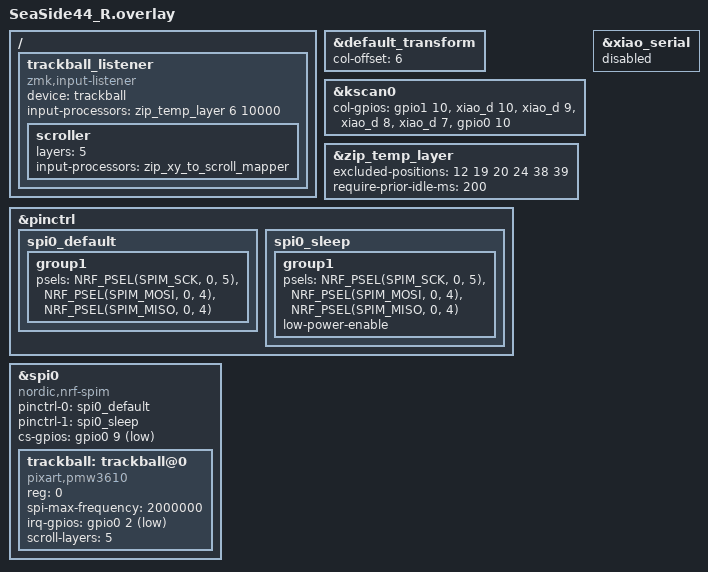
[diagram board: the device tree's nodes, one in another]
#include "SeaSide44.dtsi"
#include <input/processors.dtsi>

&default_transform {
    col-offset = <6>;
};

/* キーマトリクスの設定 */
// 上が外側、下が内側カラムcol番号と実際の配置が直感と逆になってる
&kscan0 {
        col-gpios
            = <&gpio1 10 GPIO_ACTIVE_HIGH>
            , <&xiao_d 10 GPIO_ACTIVE_HIGH>
            , <&xiao_d 9 GPIO_ACTIVE_HIGH> 
            , <&xiao_d 8 GPIO_ACTIVE_HIGH> 
            , <&xiao_d 7 GPIO_ACTIVE_HIGH> 
            , <&gpio0 10 GPIO_ACTIVE_HIGH>
            ;
};

/* AML: Input Processor: excluded-positions */
/* こちらに設定しているキー以外が入力されたらAML解除 */
&zip_temp_layer {
    excluded-positions = <
        12 // LCTRL
        19 // J
        20 // K
        24 // LSHIFT
        38 // LEFT_WIN
        39 // LEFT_ALT
    >;
    require-prior-idle-ms = <200>;
};

/* Trackball のリスナー */ 
/ {
    trackball_listener {
        compatible = "zmk,input-listener";
        device = <&trackball>;

        input-processors = <&zip_temp_layer 6 10000>;
    
        // セミコロン長押しで入る SCROLL(L5) が有効な間だけ
        // トラックボールの XY をスクロールイベントに変換する
        scroller {
            layers = <5>;
            input-processors = <&zip_xy_to_scroll_mapper>;
            // 必要なら感度を調整（例: 倍率や加速度を入れる場合）
            // scale-x = <1>;
            // scale-y = <1>;
            // invert-y;  // 逆方向が好みなら有効化
        };
    };
};

/* SPI 設定 */
&pinctrl {
    spi0_default: spi0_default {
        group1 {
            psels = <NRF_PSEL(SPIM_SCK, 0, 5)>,
                <NRF_PSEL(SPIM_MOSI, 0, 4)>,
                <NRF_PSEL(SPIM_MISO, 0, 4)>;
        };
    };

    spi0_sleep: spi0_sleep {
        group1 {
            psels = <NRF_PSEL(SPIM_SCK, 0, 5)>,
                <NRF_PSEL(SPIM_MOSI, 0, 4)>,
                <NRF_PSEL(SPIM_MISO, 0, 4)>;
            low-power-enable;
        };
    };
};

/* シリアルを無効化 */
&xiao_serial { status = "disabled"; };

/* SPI デバイス (トラックボール) */
&spi0 {
    status = "okay";
    compatible = "nordic,nrf-spim";
    pinctrl-0 = <&spi0_default>;
    pinctrl-1 = <&spi0_sleep>;
    pinctrl-names = "default", "sleep";
    cs-gpios = <&gpio0 9 GPIO_ACTIVE_LOW>;

    trackball: trackball@0 {
        status = "okay";
        compatible = "pixart,pmw3610";
        reg = <0>;
        spi-max-frequency = <2000000>;
        irq-gpios = <&gpio0 2 (GPIO_ACTIVE_LOW | GPIO_PULL_UP)>;
        // Input ProcessorにてAMLの設定を行っているため、zmk-pmw3610-driverは無効化する
        // automouse-layer = <4>; //ここをコメントアウトするとオートマウスレイヤーがオフになる 
        scroll-layers = <5>;
    };
};

